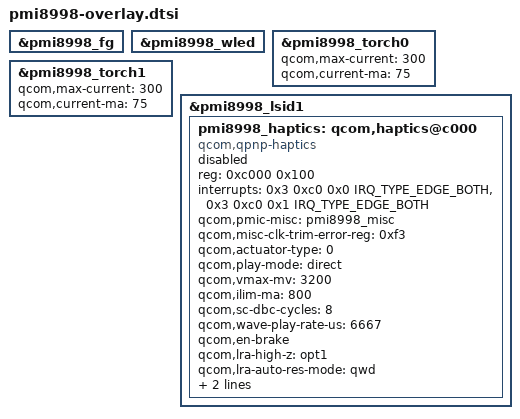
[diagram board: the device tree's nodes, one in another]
&pmi8998_fg {
    /delete-property/ qcom,hold-soc-while-full;
};

#ifndef CONFIG_BACKLIGHT_QCOM_WLED_MAINLINE
&pmi8998_wled {
    /delete-property/ qcom,auto-calibration;
};
#endif

&pmi8998_torch0 {
    qcom,max-current = <300>;
    qcom,current-ma = <75>;
};

&pmi8998_torch1 {
    qcom,max-current = <300>;
    qcom,current-ma = <75>;
};

&pmi8998_lsid1 {
    /delete-node/ qcom,haptic@c000;
    pmi8998_haptics: qcom,haptics@c000 {
        compatible = "qcom,qpnp-haptics";
        reg = <0xc000 0x100>;
        interrupts = <0x3 0xc0 0x0 IRQ_TYPE_EDGE_BOTH>,
        <0x3 0xc0 0x1 IRQ_TYPE_EDGE_BOTH>;
        interrupt-names = "hap-sc-irq", "hap-play-irq";
        qcom,pmic-misc = <&pmi8998_misc>;
        qcom,misc-clk-trim-error-reg = <0xf3>;
        qcom,actuator-type = <0>;
        qcom,play-mode = "direct";
        qcom,vmax-mv = <3200>;
        qcom,ilim-ma = <800>;
        qcom,sc-dbc-cycles = <8>;
        qcom,wave-play-rate-us = <6667>;
        qcom,en-brake;
        qcom,lra-high-z = "opt1";
        qcom,lra-auto-res-mode = "qwd";
        qcom,lra-res-cal-period = <4>;
        qcom,pmic-revid = <&pmi8998_revid>;
        status = "disabled";
    };
};
